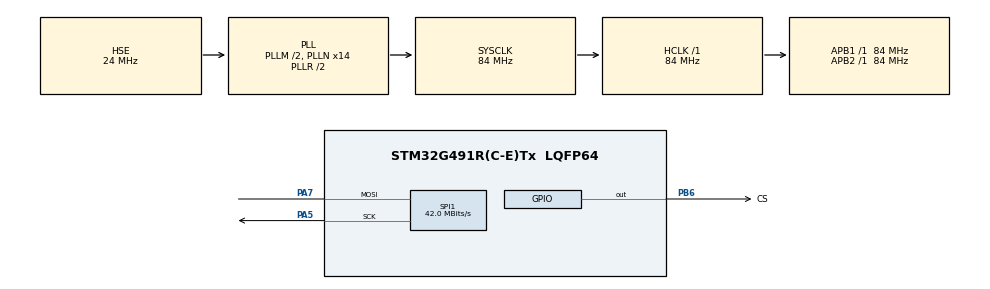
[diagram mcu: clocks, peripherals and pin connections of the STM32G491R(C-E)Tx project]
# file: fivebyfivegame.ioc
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Mcu.Family=STM32G4
Mcu.Name=STM32G491R(C-E)Tx
Mcu.Package=LQFP64
NVIC.PriorityGroup=NVIC_PRIORITYGROUP_4
PA5.Mode=Simplex_Bidirectional_Master
PA5.Signal=SPI1_SCK
PA7.Mode=Simplex_Bidirectional_Master
PA7.Signal=SPI1_MOSI
PB6.GPIO_Label=CS
PB6.Signal=GPIO_Output
PF0-OSC_IN.Mode=HSE-External-Oscillator
PF0-OSC_IN.Signal=RCC_OSC_IN
PF1-OSC_OUT.Mode=HSE-External-Oscillator
PF1-OSC_OUT.Signal=RCC_OSC_OUT
ProjectManager.HeapSize=0x200
ProjectManager.StackSize=0x400
ProjectManager.TargetToolchain=STM32CubeIDE
RCC.ADC12Freq_Value=84000000
RCC.ADC345Freq_Value=84000000
RCC.AHBFreq_Value=84000000
RCC.APB1Freq_Value=84000000
RCC.APB1TimFreq_Value=84000000
RCC.APB2Freq_Value=84000000
RCC.APB2TimFreq_Value=84000000
RCC.CortexFreq_Value=84000000
RCC.EXTERNAL_CLOCK_VALUE=12288000
RCC.HCLKFreq_Value=84000000
RCC.HSE_VALUE=24000000
RCC.HSI48_VALUE=48000000
RCC.HSI_VALUE=16000000
RCC.LSE_VALUE=32768
RCC.PLLM=RCC_PLLM_DIV2
RCC.PLLN=14
RCC.PLLSourceVirtual=RCC_PLLSOURCE_HSE
RCC.RTCClockSelection=RCC_RTCCLKSOURCE_LSE
RCC.SYSCLKFreq_VALUE=84000000
RCC.SYSCLKSource=RCC_SYSCLKSOURCE_PLLCLK
RCC.USBFreq_Value=48000000
RCC.VCOOutputFreq_Value=168000000
SPI1.CalculateBaudRate=42.0 MBits/s
SPI1.Direction=SPI_DIRECTION_1LINE
SPI1.Mode=SPI_MODE_MASTER
SPI1.VirtualType=VM_MASTER
board=NUCLEO-G491RE

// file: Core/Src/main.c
/* USER CODE BEGIN Header */
/**
  ******************************************************************************
  * @file           : main.c
  * @brief          : Main program body
  ******************************************************************************
  * @attention
  *
  * Copyright (c) 2023 STMicroelectronics.
  * All rights reserved.
  *
  * This software is licensed under terms that can be found in the LICENSE file
  * in the root directory of this software component.
  * If no LICENSE file comes with this software, it is provided AS-IS.
  *
  ******************************************************************************
  */
/* USER CODE END Header */
#include "main.h"
#include "7219.h"

SPI_HandleTypeDef hspi1;

void SystemClock_Config(void);
static void MX_GPIO_Init(void);
static void MX_SPI1_Init(void);

/* USER CODE BEGIN 0 */

uint8_t disp1ay[38][8]={
{0x3C,0x42,0x42,0x42,0x42,0x42,0x42,0x3C},  //0
{0x10,0x30,0x50,0x10,0x10,0x10,0x10,0x7c},  //1
{0x7E,0x2,0x2,0x7E,0x40,0x40,0x40,0x7E},    //2
{0x3E,0x2,0x2,0x3E,0x2,0x2,0x3E,0x0},       //3
{0x8,0x18,0x28,0x48,0xFE,0x8,0x8,0x8},      //4
{0x3C,0x20,0x20,0x3C,0x4,0x4,0x3C,0x0},//5
{0x3C,0x20,0x20,0x3C,0x24,0x24,0x3C,0x0},//6
{0x3E,0x22,0x4,0x8,0x8,0x8,0x8,0x8},//7
{0x0,0x3E,0x22,0x22,0x3E,0x22,0x22,0x3E},//8
{0x3E,0x22,0x22,0x3E,0x2,0x2,0x2,0x3E},//9
{0x18,0x24,0x42,0x42,0x7E,0x42,0x42,0x42},//A
{0x3C,0x22,0x22,0x3c,0x22,0x22,0x3C,0x0},//B
{0x3C,0x40,0x40,0x40,0x40,0x40,0x40,0x3C},//C
{0x7C,0x22,0x22,0x22,0x22,0x22,0x22,0x7C},//D
{0x7C,0x40,0x40,0x7C,0x40,0x40,0x40,0x7C},//E
{0x7C,0x40,0x40,0x7C,0x40,0x40,0x40,0x40},//F
{0x3C,0x40,0x40,0x40,0x4c,0x44,0x44,0x3C},//G
{0x44,0x44,0x44,0x7C,0x44,0x44,0x44,0x44},//H
{0x7C,0x10,0x10,0x10,0x10,0x10,0x10,0x7C},//I
{0x3C,0x8,0x8,0x8,0x8,0x8,0x48,0x30},//J
{0x0,0x24,0x28,0x30,0x20,0x30,0x28,0x24},//K
{0x40,0x40,0x40,0x40,0x40,0x40,0x40,0x7C},//L
{0x81,0xC3,0xA5,0x99,0x81,0x81,0x81,0x81},//M
{0x0,0x42,0x62,0x52,0x4A,0x46,0x42,0x0},//N
{0x3C,0x42,0x42,0x42,0x42,0x42,0x42,0x3C},//O
{0x3C,0x22,0x22,0x22,0x3C,0x20,0x20,0x20},//P
{0x1C,0x22,0x22,0x22,0x22,0x26,0x22,0x1D},//Q
{0x3C,0x22,0x22,0x22,0x3C,0x24,0x22,0x21},//R
{0x0,0x1E,0x20,0x20,0x3E,0x2,0x2,0x3C},//S
{0x0,0x3E,0x8,0x8,0x8,0x8,0x8,0x8},//T
{0x42,0x42,0x42,0x42,0x42,0x42,0x22,0x1C},//U
{0x42,0x42,0x42,0x42,0x42,0x42,0x24,0x18},//V
{0x0,0x49,0x49,0x49,0x49,0x2A,0x1C,0x0},//W
{0x0,0x41,0x22,0x14,0x8,0x14,0x22,0x41},//X
{0x41,0x22,0x14,0x8,0x8,0x8,0x8,0x8},//Y
{0x0,0x7F,0x2,0x4,0x8,0x10,0x20,0x7F},//Z
};

static void write_reg(uint8_t reg, uint8_t value)
{
  uint8_t tx_data[2] = {reg, value };
  HAL_GPIO_WritePin(CS_GPIO_Port, CS_Pin, GPIO_PIN_RESET);
  HAL_SPI_Transmit(&hspi1, tx_data, sizeof(tx_data),100);
  HAL_GPIO_WritePin(CS_GPIO_Port, CS_Pin, GPIO_PIN_SET);
}

static void max7219_init_8x8MAT() {
  write_reg(0x09, 0x00);       //  no decoding
  write_reg(0x0a, 0x03);       //  brightness intensity
  write_reg(0x0b, 0x07);       //  scan limit = 8 LEDs
  write_reg(0x0c, 0x01);       //  power down =0,normal mode = 1
  write_reg(0x0f, 0x00);       //  no test display

}

/* USER CODE END 0 */

int main(void)
{

  /* MCU Configuration--------------------------------------------------------*/

  /* Reset of all peripherals, Initializes the Flash interface and the Systick. */
  HAL_Init();

  /* Configure the system clock */
  SystemClock_Config();

  /* Initialize all configured peripherals */
  MX_GPIO_Init();
  MX_SPI1_Init();

  /* Infinite loop */
  /* USER CODE BEGIN WHILE */
//  max7219_Init(0x01);
//    HAL_Delay(10);
//    max7219_Decode_On();
    /* USER CODE END 2 */
  uint8_t tx_buffer[] = { 0x06, 0x0F };
  HAL_SPI_Transmit_IT(&hspi1, tx_buffer, sizeof(tx_buffer));
    while (1)
    {
    	  HAL_SPI_Transmit_IT(&hspi1, tx_buffer, sizeof(tx_buffer));
    }
}

void SystemClock_Config(void)
{
  RCC_OscInitTypeDef RCC_OscInitStruct = {0};
  RCC_ClkInitTypeDef RCC_ClkInitStruct = {0};

  /** Configure the main internal regulator output voltage
  */
  HAL_PWREx_ControlVoltageScaling(PWR_REGULATOR_VOLTAGE_SCALE1);

  /** Initializes the RCC Oscillators according to the specified parameters
  * in the RCC_OscInitTypeDef structure.
  */
  RCC_OscInitStruct.OscillatorType = RCC_OSCILLATORTYPE_HSE;
  RCC_OscInitStruct.HSEState = RCC_HSE_ON;
  RCC_OscInitStruct.PLL.PLLState = RCC_PLL_ON;
  RCC_OscInitStruct.PLL.PLLSource = RCC_PLLSOURCE_HSE;
  RCC_OscInitStruct.PLL.PLLM = RCC_PLLM_DIV2;
  RCC_OscInitStruct.PLL.PLLN = 14;
  RCC_OscInitStruct.PLL.PLLP = RCC_PLLP_DIV2;
  RCC_OscInitStruct.PLL.PLLQ = RCC_PLLQ_DIV2;
  RCC_OscInitStruct.PLL.PLLR = RCC_PLLR_DIV2;
  if (HAL_RCC_OscConfig(&RCC_OscInitStruct) != HAL_OK)
  {
    Error_Handler();
  }

  /** Initializes the CPU, AHB and APB buses clocks
  */
  RCC_ClkInitStruct.ClockType = RCC_CLOCKTYPE_HCLK|RCC_CLOCKTYPE_SYSCLK
                              |RCC_CLOCKTYPE_PCLK1|RCC_CLOCKTYPE_PCLK2;
  RCC_ClkInitStruct.SYSCLKSource = RCC_SYSCLKSOURCE_PLLCLK;
  RCC_ClkInitStruct.AHBCLKDivider = RCC_SYSCLK_DIV1;
  RCC_ClkInitStruct.APB1CLKDivider = RCC_HCLK_DIV1;
  RCC_ClkInitStruct.APB2CLKDivider = RCC_HCLK_DIV1;

  if (HAL_RCC_ClockConfig(&RCC_ClkInitStruct, FLASH_LATENCY_2) != HAL_OK)
  {
    Error_Handler();
  }
}

static void MX_SPI1_Init(void)
{

  /* SPI1 parameter configuration*/
  hspi1.Instance = SPI1;
  hspi1.Init.Mode = SPI_MODE_MASTER;
  hspi1.Init.Direction = SPI_DIRECTION_1LINE;
  hspi1.Init.DataSize = SPI_DATASIZE_8BIT;
  hspi1.Init.CLKPolarity = SPI_POLARITY_LOW;
  hspi1.Init.CLKPhase = SPI_PHASE_1EDGE;
  hspi1.Init.NSS = SPI_NSS_SOFT;
  hspi1.Init.BaudRatePrescaler = SPI_BAUDRATEPRESCALER_2;
  hspi1.Init.FirstBit = SPI_FIRSTBIT_MSB;
  hspi1.Init.TIMode = SPI_TIMODE_DISABLE;
  hspi1.Init.CRCCalculation = SPI_CRCCALCULATION_DISABLE;
  hspi1.Init.CRCPolynomial = 7;
  hspi1.Init.CRCLength = SPI_CRC_LENGTH_DATASIZE;
  hspi1.Init.NSSPMode = SPI_NSS_PULSE_ENABLE;
  if (HAL_SPI_Init(&hspi1) != HAL_OK)
  {
    Error_Handler();
  }

}

static void MX_GPIO_Init(void)
{
  GPIO_InitTypeDef GPIO_InitStruct = {0};

  /* GPIO Ports Clock Enable */
  __HAL_RCC_GPIOF_CLK_ENABLE();
  __HAL_RCC_GPIOA_CLK_ENABLE();
  __HAL_RCC_GPIOB_CLK_ENABLE();

  /*Configure GPIO pin Output Level */
  HAL_GPIO_WritePin(CS_GPIO_Port, CS_Pin, GPIO_PIN_RESET);

  /*Configure GPIO pin : CS_Pin */
  GPIO_InitStruct.Pin = CS_Pin;
  GPIO_InitStruct.Mode = GPIO_MODE_OUTPUT_PP;
  GPIO_InitStruct.Pull = GPIO_NOPULL;
  GPIO_InitStruct.Speed = GPIO_SPEED_FREQ_LOW;
  HAL_GPIO_Init(CS_GPIO_Port, &GPIO_InitStruct);

}

void Error_Handler(void)
{
  __disable_irq();
  while (1)
  {
  }
}
